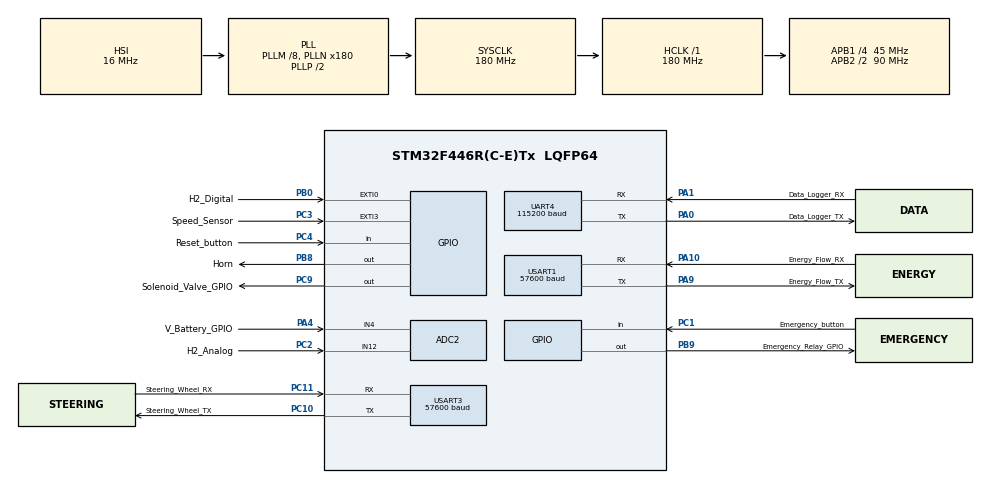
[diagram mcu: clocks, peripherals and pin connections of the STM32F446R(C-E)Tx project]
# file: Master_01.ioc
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ADC2.Channel-0\#ChannelRegularConversion=ADC_CHANNEL_12
ADC2.Channel-1\#ChannelRegularConversion=ADC_CHANNEL_4
ADC2.ClockPrescaler=ADC_CLOCK_SYNC_PCLK_DIV8
ADC2.ContinuousConvMode=ENABLE
ADC2.DMAContinuousRequests=ENABLE
ADC2.EOCSelection=ADC_EOC_SINGLE_CONV
ADC2.ExternalTrigConv=ADC_SOFTWARE_START
ADC2.ExternalTrigConvEdge=ADC_EXTERNALTRIGCONVEDGE_NONE
ADC2.NbrOfConversion=2
ADC2.NbrOfConversionFlag=1
ADC2.Rank-0\#ChannelRegularConversion=1
ADC2.Rank-1\#ChannelRegularConversion=2
ADC2.SamplingTime-0\#ChannelRegularConversion=ADC_SAMPLETIME_480CYCLES
ADC2.SamplingTime-1\#ChannelRegularConversion=ADC_SAMPLETIME_480CYCLES
ADC2.ScanConvMode=ENABLE
Dma.ADC2.0.Direction=DMA_PERIPH_TO_MEMORY
Dma.ADC2.0.FIFOMode=DMA_FIFOMODE_DISABLE
Dma.ADC2.0.Instance=DMA2_Stream2
Dma.ADC2.0.MemDataAlignment=DMA_MDATAALIGN_HALFWORD
Dma.ADC2.0.MemInc=DMA_MINC_ENABLE
Dma.ADC2.0.Mode=DMA_CIRCULAR
Dma.ADC2.0.PeriphDataAlignment=DMA_PDATAALIGN_HALFWORD
Dma.ADC2.0.PeriphInc=DMA_PINC_DISABLE
Dma.ADC2.0.Priority=DMA_PRIORITY_MEDIUM
Dma.Request0=ADC2
Dma.Request1=USART3_RX
Dma.Request2=USART1_RX
Dma.USART1_RX.2.Direction=DMA_PERIPH_TO_MEMORY
Dma.USART1_RX.2.FIFOMode=DMA_FIFOMODE_DISABLE
Dma.USART1_RX.2.Instance=DMA2_Stream5
Dma.USART1_RX.2.MemDataAlignment=DMA_MDATAALIGN_BYTE
Dma.USART1_RX.2.MemInc=DMA_MINC_ENABLE
Dma.USART1_RX.2.Mode=DMA_NORMAL
Dma.USART1_RX.2.PeriphDataAlignment=DMA_PDATAALIGN_BYTE
Dma.USART1_RX.2.PeriphInc=DMA_PINC_DISABLE
Dma.USART1_RX.2.Priority=DMA_PRIORITY_LOW
Dma.USART3_RX.1.Direction=DMA_PERIPH_TO_MEMORY
Dma.USART3_RX.1.FIFOMode=DMA_FIFOMODE_DISABLE
Dma.USART3_RX.1.Instance=DMA1_Stream1
Dma.USART3_RX.1.MemDataAlignment=DMA_MDATAALIGN_BYTE
Dma.USART3_RX.1.MemInc=DMA_MINC_ENABLE
Dma.USART3_RX.1.Mode=DMA_NORMAL
Dma.USART3_RX.1.PeriphDataAlignment=DMA_PDATAALIGN_BYTE
Dma.USART3_RX.1.PeriphInc=DMA_PINC_DISABLE
Dma.USART3_RX.1.Priority=DMA_PRIORITY_LOW
Mcu.Family=STM32F4
Mcu.Name=STM32F446R(C-E)Tx
Mcu.Package=LQFP64
NVIC.DMA1_Stream1_IRQn=true\:0\:0\:false\:false\:true\:false\:true
NVIC.DMA2_Stream2_IRQn=true\:0\:0\:false\:false\:true\:false\:true
NVIC.DMA2_Stream5_IRQn=true\:0\:0\:false\:false\:true\:false\:true
NVIC.EXTI0_IRQn=true\:0\:2\:false\:false\:true\:true\:true
NVIC.EXTI3_IRQn=true\:0\:0\:false\:false\:true\:true\:true
NVIC.PriorityGroup=NVIC_PRIORITYGROUP_0
NVIC.TIM2_IRQn=true\:0\:0\:false\:false\:true\:true\:true
NVIC.TIM6_DAC_IRQn=true\:0\:0\:false\:false\:true\:true\:true
NVIC.TIM7_IRQn=true\:0\:0\:false\:false\:true\:true\:true
NVIC.UART4_IRQn=true\:0\:0\:false\:false\:true\:true\:true
NVIC.USART1_IRQn=true\:0\:1\:false\:false\:true\:true\:true
NVIC.USART3_IRQn=true\:0\:1\:false\:false\:true\:true\:true
PA0-WKUP.GPIO_Label=Data_Logger_TX
PA0-WKUP.Mode=Asynchronous
PA0-WKUP.Signal=UART4_TX
PA1.GPIO_Label=Data_Logger_RX
PA1.Mode=Asynchronous
PA1.Signal=UART4_RX
PA10.GPIO_Label=Energy_Flow_RX
PA10.Mode=Asynchronous
PA10.Signal=USART1_RX
PA13.GPIO_Label=TMS
PA13.Signal=SYS_JTMS-SWDIO
PA14.GPIO_Label=TCK
PA14.Signal=SYS_JTCK-SWCLK
PA4.GPIO_Label=V_Battery_GPIO
PA4.Signal=ADCx_IN4
PA9.GPIO_Label=Energy_Flow_TX
PA9.Mode=Asynchronous
PA9.Signal=USART1_TX
PB0.GPIO_Label=H2_Digital
PB0.GPIO_ModeDefaultEXTI=GPIO_MODE_IT_FALLING
PB0.GPIO_PuPd=GPIO_PULLUP
PB0.Signal=GPXTI0
PB3.GPIO_Label=SWO
PB3.Signal=SYS_JTDO-SWO
PB8.GPIO_Label=Horn
PB8.Signal=GPIO_Output
PB9.GPIO_Label=Emergency_Relay_GPIO
PB9.Signal=GPIO_Output
PC1.GPIO_Label=Emergency_button
PC1.Signal=GPIO_Input
PC10.GPIO_Label=Steering_Wheel_TX
PC10.Mode=Asynchronous
PC10.Signal=USART3_TX
PC11.GPIO_Label=Steering_Wheel_RX
PC11.Mode=Asynchronous
PC11.Signal=USART3_RX
PC14-OSC32_IN.Mode=LSE-External-Oscillator
PC14-OSC32_IN.Signal=RCC_OSC32_IN
PC15-OSC32_OUT.Mode=LSE-External-Oscillator
PC15-OSC32_OUT.Signal=RCC_OSC32_OUT
PC2.GPIO_Label=H2_Analog
PC2.Signal=ADCx_IN12
PC3.GPIO_Label=Speed_Sensor
PC3.GPIO_PuPd=GPIO_PULLUP
PC3.Signal=GPXTI3
PC4.GPIO_Label=Reset_button
PC4.Signal=GPIO_Input
PC9.GPIO_Label=Solenoid_Valve_GPIO
PC9.Signal=GPIO_Output
PH0-OSC_IN.Mode=HSE-External-Oscillator
PH0-OSC_IN.Signal=RCC_OSC_IN
PH1-OSC_OUT.Mode=HSE-External-Oscillator
PH1-OSC_OUT.Signal=RCC_OSC_OUT
ProjectManager.HeapSize=0x200
ProjectManager.StackSize=0x400
ProjectManager.TargetToolchain=STM32CubeIDE
RCC.48MHZClocksFreq_Value=84000000
RCC.AHBFreq_Value=180000000
RCC.APB1CLKDivider=RCC_HCLK_DIV4
RCC.APB1Freq_Value=45000000
RCC.APB1TimFreq_Value=90000000
RCC.APB2CLKDivider=RCC_HCLK_DIV2
RCC.APB2Freq_Value=90000000
RCC.APB2TimFreq_Value=180000000
RCC.CortexFreq_Value=180000000
RCC.FLatency-AdvancedSettings=FLASH_LATENCY_5
RCC.HCLKFreq_Value=180000000
RCC.HSE_VALUE=8000000
RCC.HSI_VALUE=16000000
RCC.PLLM=8
RCC.PLLN=180
RCC.SYSCLKFreq_VALUE=180000000
RCC.SYSCLKSource=RCC_SYSCLKSOURCE_PLLCLK
RCC.USBFreq_Value=180000000
RCC.VCOOutputFreq_Value=360000000
SH.ADCx_IN12.0=ADC2_IN12,IN12
SH.ADCx_IN4.0=ADC2_IN4,IN4
TIM2.Period=49
TIM2.Prescaler=8399
TIM2.TIM_MasterOutputTrigger=TIM_TRGO_UPDATE
TIM6.Period=100-1
TIM6.Prescaler=90-1
TIM7.AutoReloadPreload=TIM_AUTORELOAD_PRELOAD_ENABLE
TIM7.Period=1000-1
TIM7.Prescaler=90-1
UART4.BaudRate=115200
UART4.OverSampling=UART_OVERSAMPLING_8
UART4.VirtualMode=Asynchronous
USART1.BaudRate=57600
USART1.OverSampling=UART_OVERSAMPLING_8
USART1.VirtualMode=VM_ASYNC
USART3.BaudRate=57600
USART3.OverSampling=UART_OVERSAMPLING_8
USART3.VirtualMode=VM_ASYNC
VP_IWDG_VS_IWDG.Mode=IWDG_Activate
VP_TIM2_VS_ClockSourceINT.Mode=Internal
VP_TIM6_VS_ClockSourceINT.Mode=Enable_Timer
VP_TIM7_VS_ClockSourceINT.Mode=Enable_Timer
board=NUCLEO-F446RE

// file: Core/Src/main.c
/* USER CODE BEGIN Header */
/**
  ******************************************************************************
  * @file           : main.c
  * @brief          : Main program body
  ******************************************************************************
  * @attention
  *
  * <h2><center>&copy; Copyright (c) 2021 STMicroelectronics.
  * All rights reserved.</center></h2>
  *
  * This software component is licensed by ST under BSD 3-Clause license,
  * the "License"; You may not use this file except in compliance with the
  * License. You may obtain a copy of the License at:
  *                        opensource.org/licenses/BSD-3-Clause
  *
  ******************************************************************************
  */
/* USER CODE END Header */
#include "main.h"
#include "adc.h"
#include "dma.h"
#include "iwdg.h"
#include "tim.h"
#include "usart.h"
#include "gpio.h"

/* USER CODE BEGIN Includes */
#include "../../Hydrogreen/hydrogreen.h"
/* USER CODE END Includes */

void SystemClock_Config(void);

int main(void)
{

  /* MCU Configuration--------------------------------------------------------*/

  /* Reset of all peripherals, Initializes the Flash interface and the Systick. */
  HAL_Init();

  /* Configure the system clock */
  SystemClock_Config();

  /* Initialize all configured peripherals */
  MX_GPIO_Init();
  MX_DMA_Init();
  MX_UART4_Init();
  MX_USART1_UART_Init();
  MX_TIM2_Init();
  MX_ADC2_Init();
  MX_USART3_UART_Init();
  MX_IWDG_Init();
  MX_TIM6_Init();
  MX_TIM7_Init();
  /* USER CODE BEGIN 2 */
  hydrogreen_main();
  /* USER CODE END 2 */

  /* Infinite loop */
  while (1)
  {

  }
}

void SystemClock_Config(void)
{
  RCC_OscInitTypeDef RCC_OscInitStruct = {0};
  RCC_ClkInitTypeDef RCC_ClkInitStruct = {0};

  /** Configure the main internal regulator output voltage
  */
  __HAL_RCC_PWR_CLK_ENABLE();
  __HAL_PWR_VOLTAGESCALING_CONFIG(PWR_REGULATOR_VOLTAGE_SCALE1);
  /** Initializes the RCC Oscillators according to the specified parameters
  * in the RCC_OscInitTypeDef structure.
  */
  RCC_OscInitStruct.OscillatorType = RCC_OSCILLATORTYPE_HSI|RCC_OSCILLATORTYPE_LSI;
  RCC_OscInitStruct.HSIState = RCC_HSI_ON;
  RCC_OscInitStruct.HSICalibrationValue = RCC_HSICALIBRATION_DEFAULT;
  RCC_OscInitStruct.LSIState = RCC_LSI_ON;
  RCC_OscInitStruct.PLL.PLLState = RCC_PLL_ON;
  RCC_OscInitStruct.PLL.PLLSource = RCC_PLLSOURCE_HSI;
  RCC_OscInitStruct.PLL.PLLM = 8;
  RCC_OscInitStruct.PLL.PLLN = 180;
  RCC_OscInitStruct.PLL.PLLP = RCC_PLLP_DIV2;
  RCC_OscInitStruct.PLL.PLLQ = 2;
  RCC_OscInitStruct.PLL.PLLR = 2;
  if (HAL_RCC_OscConfig(&RCC_OscInitStruct) != HAL_OK)
  {
    Error_Handler();
  }
  /** Activate the Over-Drive mode
  */
  if (HAL_PWREx_EnableOverDrive() != HAL_OK)
  {
    Error_Handler();
  }
  /** Initializes the CPU, AHB and APB buses clocks
  */
  RCC_ClkInitStruct.ClockType = RCC_CLOCKTYPE_HCLK|RCC_CLOCKTYPE_SYSCLK
                              |RCC_CLOCKTYPE_PCLK1|RCC_CLOCKTYPE_PCLK2;
  RCC_ClkInitStruct.SYSCLKSource = RCC_SYSCLKSOURCE_PLLCLK;
  RCC_ClkInitStruct.AHBCLKDivider = RCC_SYSCLK_DIV1;
  RCC_ClkInitStruct.APB1CLKDivider = RCC_HCLK_DIV4;
  RCC_ClkInitStruct.APB2CLKDivider = RCC_HCLK_DIV2;

  if (HAL_RCC_ClockConfig(&RCC_ClkInitStruct, FLASH_LATENCY_5) != HAL_OK)
  {
    Error_Handler();
  }
}

void Error_Handler(void)
{
  /* USER CODE BEGIN Error_Handler_Debug */
	hydrogreen_hardFault();
  /* User can add his own implementation to report the HAL error return state */

  /* USER CODE END Error_Handler_Debug */
}

/************************ (C) COPYRIGHT STMicroelectronics *****END OF FILE****/
